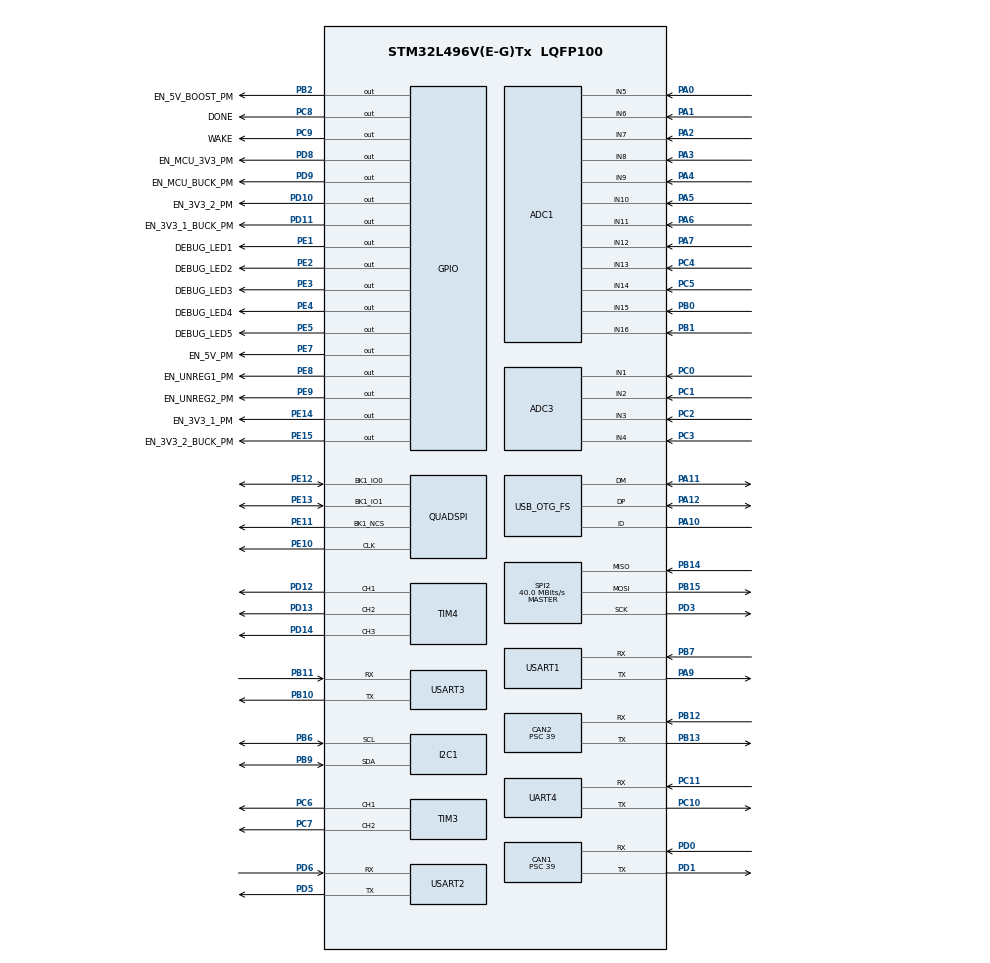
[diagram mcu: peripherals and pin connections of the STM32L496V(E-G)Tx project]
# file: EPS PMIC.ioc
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ADC1.Channel-0\#ChannelRegularConversion=ADC_CHANNEL_5
ADC1.Channel-1\#ChannelRegularConversion=ADC_CHANNEL_6
ADC1.Channel-10\#ChannelRegularConversion=ADC_CHANNEL_15
ADC1.Channel-11\#ChannelRegularConversion=ADC_CHANNEL_16
ADC1.Channel-12\#ChannelRegularConversion=ADC_CHANNEL_TEMPSENSOR
ADC1.Channel-13\#ChannelRegularConversion=ADC_CHANNEL_VBAT
ADC1.Channel-14\#ChannelRegularConversion=ADC_CHANNEL_VREFINT
ADC1.Channel-2\#ChannelRegularConversion=ADC_CHANNEL_7
ADC1.Channel-3\#ChannelRegularConversion=ADC_CHANNEL_8
ADC1.Channel-4\#ChannelRegularConversion=ADC_CHANNEL_9
ADC1.Channel-5\#ChannelRegularConversion=ADC_CHANNEL_10
ADC1.Channel-6\#ChannelRegularConversion=ADC_CHANNEL_11
ADC1.Channel-7\#ChannelRegularConversion=ADC_CHANNEL_12
ADC1.Channel-8\#ChannelRegularConversion=ADC_CHANNEL_13
ADC1.Channel-9\#ChannelRegularConversion=ADC_CHANNEL_14
ADC1.ContinuousConvMode=ENABLE
ADC1.DMAContinuousRequests=ENABLE
ADC1.EOCSelection=ADC_EOC_SEQ_CONV
ADC1.NbrOfConversion=15
ADC1.NbrOfConversionFlag=1
ADC1.OffsetNumber-0\#ChannelRegularConversion=ADC_OFFSET_NONE
ADC1.OffsetNumber-1\#ChannelRegularConversion=ADC_OFFSET_NONE
ADC1.OffsetNumber-10\#ChannelRegularConversion=ADC_OFFSET_NONE
ADC1.OffsetNumber-11\#ChannelRegularConversion=ADC_OFFSET_NONE
ADC1.OffsetNumber-12\#ChannelRegularConversion=ADC_OFFSET_NONE
ADC1.OffsetNumber-13\#ChannelRegularConversion=ADC_OFFSET_NONE
ADC1.OffsetNumber-14\#ChannelRegularConversion=ADC_OFFSET_NONE
ADC1.OffsetNumber-2\#ChannelRegularConversion=ADC_OFFSET_NONE
ADC1.OffsetNumber-3\#ChannelRegularConversion=ADC_OFFSET_NONE
ADC1.OffsetNumber-4\#ChannelRegularConversion=ADC_OFFSET_NONE
ADC1.OffsetNumber-5\#ChannelRegularConversion=ADC_OFFSET_NONE
ADC1.OffsetNumber-6\#ChannelRegularConversion=ADC_OFFSET_NONE
ADC1.OffsetNumber-7\#ChannelRegularConversion=ADC_OFFSET_NONE
ADC1.OffsetNumber-8\#ChannelRegularConversion=ADC_OFFSET_NONE
ADC1.OffsetNumber-9\#ChannelRegularConversion=ADC_OFFSET_NONE
ADC1.Rank-0\#ChannelRegularConversion=1
ADC1.Rank-1\#ChannelRegularConversion=2
ADC1.Rank-10\#ChannelRegularConversion=11
ADC1.Rank-11\#ChannelRegularConversion=12
ADC1.Rank-12\#ChannelRegularConversion=13
ADC1.Rank-13\#ChannelRegularConversion=14
ADC1.Rank-14\#ChannelRegularConversion=15
ADC1.Rank-2\#ChannelRegularConversion=3
ADC1.Rank-3\#ChannelRegularConversion=4
ADC1.Rank-4\#ChannelRegularConversion=5
ADC1.Rank-5\#ChannelRegularConversion=6
ADC1.Rank-6\#ChannelRegularConversion=7
ADC1.Rank-7\#ChannelRegularConversion=8
ADC1.Rank-8\#ChannelRegularConversion=9
ADC1.Rank-9\#ChannelRegularConversion=10
ADC1.SamplingTime-0\#ChannelRegularConversion=ADC_SAMPLETIME_247CYCLES_5
ADC1.SamplingTime-1\#ChannelRegularConversion=ADC_SAMPLETIME_247CYCLES_5
ADC1.SamplingTime-10\#ChannelRegularConversion=ADC_SAMPLETIME_247CYCLES_5
ADC1.SamplingTime-11\#ChannelRegularConversion=ADC_SAMPLETIME_247CYCLES_5
ADC1.SamplingTime-12\#ChannelRegularConversion=ADC_SAMPLETIME_247CYCLES_5
ADC1.SamplingTime-13\#ChannelRegularConversion=ADC_SAMPLETIME_247CYCLES_5
ADC1.SamplingTime-14\#ChannelRegularConversion=ADC_SAMPLETIME_247CYCLES_5
ADC1.SamplingTime-2\#ChannelRegularConversion=ADC_SAMPLETIME_247CYCLES_5
ADC1.SamplingTime-3\#ChannelRegularConversion=ADC_SAMPLETIME_247CYCLES_5
ADC1.SamplingTime-4\#ChannelRegularConversion=ADC_SAMPLETIME_247CYCLES_5
ADC1.SamplingTime-5\#ChannelRegularConversion=ADC_SAMPLETIME_247CYCLES_5
ADC1.SamplingTime-6\#ChannelRegularConversion=ADC_SAMPLETIME_247CYCLES_5
ADC1.SamplingTime-7\#ChannelRegularConversion=ADC_SAMPLETIME_247CYCLES_5
ADC1.SamplingTime-8\#ChannelRegularConversion=ADC_SAMPLETIME_247CYCLES_5
ADC1.SamplingTime-9\#ChannelRegularConversion=ADC_SAMPLETIME_247CYCLES_5
ADC1.master=1
ADC3.Channel-0\#ChannelRegularConversion=ADC_CHANNEL_1
ADC3.Channel-1\#ChannelRegularConversion=ADC_CHANNEL_2
ADC3.Channel-2\#ChannelRegularConversion=ADC_CHANNEL_3
ADC3.Channel-3\#ChannelRegularConversion=ADC_CHANNEL_4
ADC3.Channel-4\#ChannelRegularConversion=ADC_CHANNEL_TEMPSENSOR
ADC3.Channel-5\#ChannelRegularConversion=ADC_CHANNEL_VBAT
ADC3.ContinuousConvMode=ENABLE
ADC3.DMAContinuousRequests=ENABLE
ADC3.EOCSelection=ADC_EOC_SEQ_CONV
ADC3.NbrOfConversion=6
ADC3.NbrOfConversionFlag=1
ADC3.OffsetNumber-0\#ChannelRegularConversion=ADC_OFFSET_NONE
ADC3.OffsetNumber-1\#ChannelRegularConversion=ADC_OFFSET_NONE
ADC3.OffsetNumber-2\#ChannelRegularConversion=ADC_OFFSET_NONE
ADC3.OffsetNumber-3\#ChannelRegularConversion=ADC_OFFSET_NONE
ADC3.OffsetNumber-4\#ChannelRegularConversion=ADC_OFFSET_NONE
ADC3.OffsetNumber-5\#ChannelRegularConversion=ADC_OFFSET_NONE
ADC3.Rank-0\#ChannelRegularConversion=1
ADC3.Rank-1\#ChannelRegularConversion=2
ADC3.Rank-2\#ChannelRegularConversion=3
ADC3.Rank-3\#ChannelRegularConversion=4
ADC3.Rank-4\#ChannelRegularConversion=5
ADC3.Rank-5\#ChannelRegularConversion=6
ADC3.SamplingTime-0\#ChannelRegularConversion=ADC_SAMPLETIME_247CYCLES_5
ADC3.SamplingTime-1\#ChannelRegularConversion=ADC_SAMPLETIME_247CYCLES_5
ADC3.SamplingTime-2\#ChannelRegularConversion=ADC_SAMPLETIME_247CYCLES_5
ADC3.SamplingTime-3\#ChannelRegularConversion=ADC_SAMPLETIME_247CYCLES_5
ADC3.SamplingTime-4\#ChannelRegularConversion=ADC_SAMPLETIME_247CYCLES_5
ADC3.SamplingTime-5\#ChannelRegularConversion=ADC_SAMPLETIME_247CYCLES_5
CAN1.CalculateBaudRate=683760
CAN1.CalculateTimeBit=1462
CAN1.CalculateTimeQuantum=487.5
CAN1.Prescaler=39
CAN2.BS1=CAN_BS1_1TQ
CAN2.BS2=CAN_BS2_1TQ
CAN2.CalculateBaudRate=683760
CAN2.CalculateTimeBit=1462
CAN2.CalculateTimeQuantum=487.5
CAN2.Prescaler=39
Dma.ADC1.0.Direction=DMA_PERIPH_TO_MEMORY
Dma.ADC1.0.Instance=DMA1_Channel1
Dma.ADC1.0.MemDataAlignment=DMA_MDATAALIGN_HALFWORD
Dma.ADC1.0.MemInc=DMA_MINC_ENABLE
Dma.ADC1.0.Mode=DMA_CIRCULAR
Dma.ADC1.0.PeriphDataAlignment=DMA_PDATAALIGN_HALFWORD
Dma.ADC1.0.PeriphInc=DMA_PINC_DISABLE
Dma.ADC1.0.Priority=DMA_PRIORITY_HIGH
Dma.ADC3.1.Direction=DMA_PERIPH_TO_MEMORY
Dma.ADC3.1.Instance=DMA1_Channel3
Dma.ADC3.1.MemDataAlignment=DMA_MDATAALIGN_HALFWORD
Dma.ADC3.1.MemInc=DMA_MINC_ENABLE
Dma.ADC3.1.Mode=DMA_CIRCULAR
Dma.ADC3.1.PeriphDataAlignment=DMA_PDATAALIGN_HALFWORD
Dma.ADC3.1.PeriphInc=DMA_PINC_DISABLE
Dma.ADC3.1.Priority=DMA_PRIORITY_MEDIUM
Dma.Request0=ADC1
Dma.Request1=ADC3
I2C1.Timing=0x10D19CE4
Mcu.Family=STM32L4
Mcu.Name=STM32L496V(E-G)Tx
Mcu.Package=LQFP100
NVIC.DMA1_Channel1_IRQn=true\:0\:0\:false\:false\:true\:false\:true\:true
NVIC.DMA1_Channel3_IRQn=true\:0\:0\:false\:false\:true\:false\:true\:true
NVIC.PriorityGroup=NVIC_PRIORITYGROUP_4
NVIC.UART4_IRQn=true\:0\:0\:false\:false\:true\:true\:true\:true
NVIC.USART1_IRQn=true\:0\:0\:false\:false\:true\:true\:true\:true
NVIC.USART2_IRQn=true\:0\:0\:false\:false\:true\:true\:true\:true
NVIC.USART3_IRQn=true\:0\:0\:false\:false\:true\:true\:true\:true
PA0.Signal=ADCx_IN5
PA1.Signal=ADCx_IN6
PA10.Mode=OTG/Dual_Role_Device
PA10.Signal=USB_OTG_FS_ID
PA11.Mode=OTG/Dual_Role_Device
PA11.Signal=USB_OTG_FS_DM
PA12.Mode=OTG/Dual_Role_Device
PA12.Signal=USB_OTG_FS_DP
PA13\ (JTMS/SWDIO).Mode=JTAG_5_pins
PA13\ (JTMS/SWDIO).Signal=SYS_JTMS-SWDIO
PA14\ (JTCK/SWCLK).Mode=JTAG_5_pins
PA14\ (JTCK/SWCLK).Signal=SYS_JTCK-SWCLK
PA15\ (JTDI).Mode=JTAG_5_pins
PA15\ (JTDI).Signal=SYS_JTDI
PA2.Signal=ADCx_IN7
PA3.Signal=ADCx_IN8
PA4.Signal=ADCx_IN9
PA5.Signal=ADCx_IN10
PA6.Signal=ADCx_IN11
PA7.Signal=ADCx_IN12
PA9.Mode=Asynchronous
PA9.Signal=USART1_TX
PB0.Signal=ADCx_IN15
PB1.Signal=ADCx_IN16
PB10.Mode=Asynchronous
PB10.Signal=USART3_TX
PB11.Mode=Asynchronous
PB11.Signal=USART3_RX
PB12.Mode=CAN_Activate
PB12.Signal=CAN2_RX
PB13.Mode=CAN_Activate
PB13.Signal=CAN2_TX
PB14.Mode=Full_Duplex_Master
PB14.Signal=SPI2_MISO
PB15.Mode=Full_Duplex_Master
PB15.Signal=SPI2_MOSI
PB2.GPIO_Label=EN_5V_BOOST_PM
PB2.Signal=GPIO_Output
PB3\ (JTDO/TRACESWO).Mode=JTAG_5_pins
PB3\ (JTDO/TRACESWO).Signal=SYS_JTDO-SWO
PB4\ (NJTRST).Mode=JTAG_5_pins
PB4\ (NJTRST).Signal=SYS_JTRST
PB6.Mode=I2C
PB6.Signal=I2C1_SCL
PB7.Mode=Asynchronous
PB7.Signal=USART1_RX
PB9.Mode=I2C
PB9.Signal=I2C1_SDA
PC0.Signal=ADCx_IN1
PC1.Signal=ADCx_IN2
PC10.Mode=Asynchronous
PC10.Signal=UART4_TX
PC11.Mode=Asynchronous
PC11.Signal=UART4_RX
PC14-OSC32_IN\ (PC14).Mode=LSE-External-Oscillator
PC14-OSC32_IN\ (PC14).Signal=RCC_OSC32_IN
PC15-OSC32_OUT\ (PC15).Mode=LSE-External-Oscillator
PC15-OSC32_OUT\ (PC15).Signal=RCC_OSC32_OUT
PC2.Signal=ADCx_IN3
PC3.Signal=ADCx_IN4
PC4.Signal=ADCx_IN13
PC5.Signal=ADCx_IN14
PC6.Signal=S_TIM3_CH1
PC7.Signal=S_TIM3_CH2
PC8.GPIO_Label=DONE
PC8.Signal=GPIO_Output
PC9.GPIO_Label=WAKE
PC9.Signal=GPIO_Output
PD0.Mode=CAN_Activate
PD0.Signal=CAN1_RX
PD1.Mode=CAN_Activate
PD1.Signal=CAN1_TX
PD10.GPIO_Label=EN_3V3_2_PM
PD10.Signal=GPIO_Output
PD11.GPIO_Label=EN_3V3_1_BUCK_PM
PD11.Signal=GPIO_Output
PD12.Signal=S_TIM4_CH1
PD13.Signal=S_TIM4_CH2
PD14.Signal=S_TIM4_CH3
PD3.Mode=Full_Duplex_Master
PD3.Signal=SPI2_SCK
PD5.Mode=Asynchronous
PD5.Signal=USART2_TX
PD6.Mode=Asynchronous
PD6.Signal=USART2_RX
PD8.GPIO_Label=EN_MCU_3V3_PM
PD8.Signal=GPIO_Output
PD9.GPIO_Label=EN_MCU_BUCK_PM
PD9.Signal=GPIO_Output
PE1.GPIO_Label=DEBUG_LED1
PE1.Signal=GPIO_Output
PE10.Mode=Single Bank 1 2IOs
PE10.Signal=QUADSPI_CLK
PE11.Mode=Single Bank 1 2IOs
PE11.Signal=QUADSPI_BK1_NCS
PE12.Mode=Single Bank 1 2IOs
PE12.Signal=QUADSPI_BK1_IO0
PE13.Mode=Single Bank 1 2IOs
PE13.Signal=QUADSPI_BK1_IO1
PE14.GPIO_Label=EN_3V3_1_PM
PE14.Signal=GPIO_Output
PE15.GPIO_Label=EN_3V3_2_BUCK_PM
PE15.Signal=GPIO_Output
PE2.GPIO_Label=DEBUG_LED2
PE2.Signal=GPIO_Output
PE3.GPIO_Label=DEBUG_LED3
PE3.Signal=GPIO_Output
PE4.GPIO_Label=DEBUG_LED4
PE4.Signal=GPIO_Output
PE5.GPIO_Label=DEBUG_LED5
PE5.Signal=GPIO_Output
PE7.GPIO_Label=EN_5V_PM
PE7.Signal=GPIO_Output
PE8.GPIO_Label=EN_UNREG1_PM
PE8.Signal=GPIO_Output
PE9.GPIO_Label=EN_UNREG2_PM
PE9.Signal=GPIO_Output
PH0-OSC_IN\ (PH0).Mode=HSE-External-Oscillator
PH0-OSC_IN\ (PH0).Signal=RCC_OSC_IN
PH1-OSC_OUT\ (PH1).Mode=HSE-External-Oscillator
PH1-OSC_OUT\ (PH1).Signal=RCC_OSC_OUT
ProjectManager.HeapSize=0x200
ProjectManager.StackSize=0x400
ProjectManager.TargetToolchain=STM32CubeIDE
RCC.ADCFreq_Value=64000000
RCC.AHBFreq_Value=80000000
RCC.APB1Freq_Value=80000000
RCC.APB1TimFreq_Value=80000000
RCC.APB2Freq_Value=80000000
RCC.APB2TimFreq_Value=80000000
RCC.CK48CLockSelection=RCC_USBCLKSOURCE_HSI48
RCC.CortexFreq_Value=80000000
RCC.EnableCSSLSE=true
RCC.EnbaleCSS=true
RCC.HCLKFreq_Value=80000000
RCC.HSE_VALUE=16000000
RCC.HSI48_VALUE=48000000
RCC.HSI_VALUE=16000000
RCC.MSI_VALUE=4000000
RCC.PLLN=10
RCC.PLLSourceVirtual=RCC_PLLSOURCE_HSE
RCC.RTCClockSelection=RCC_RTCCLKSOURCE_LSE
RCC.SYSCLKFreq_VALUE=80000000
RCC.SYSCLKSource=RCC_SYSCLKSOURCE_PLLCLK
RCC.USBFreq_Value=48000000
RCC.VCOOutputFreq_Value=160000000
SH.ADCx_IN1.0=ADC3_IN1,IN1-Single-Ended
SH.ADCx_IN10.0=ADC1_IN10,IN10-Single-Ended
SH.ADCx_IN11.0=ADC1_IN11,IN11-Single-Ended
SH.ADCx_IN12.0=ADC1_IN12,IN12-Single-Ended
SH.ADCx_IN13.0=ADC1_IN13,IN13-Single-Ended
SH.ADCx_IN14.0=ADC1_IN14,IN14-Single-Ended
SH.ADCx_IN15.0=ADC1_IN15,IN15-Single-Ended
SH.ADCx_IN16.0=ADC1_IN16,IN16-Single-Ended
SH.ADCx_IN2.0=ADC3_IN2,IN2-Single-Ended
SH.ADCx_IN3.0=ADC3_IN3,IN3-Single-Ended
SH.ADCx_IN4.0=ADC3_IN4,IN4-Single-Ended
SH.ADCx_IN5.0=ADC1_IN5,IN5-Single-Ended
SH.ADCx_IN6.0=ADC1_IN6,IN6-Single-Ended
SH.ADCx_IN7.0=ADC1_IN7,IN7-Single-Ended
SH.ADCx_IN8.0=ADC1_IN8,IN8-Single-Ended
SH.ADCx_IN9.0=ADC1_IN9,IN9-Single-Ended
SH.S_TIM3_CH1.0=TIM3_CH1,PWM Generation1 CH1
SH.S_TIM3_CH2.0=TIM3_CH2,PWM Generation2 CH2
SH.S_TIM4_CH1.0=TIM4_CH1,PWM Generation1 CH1
SH.S_TIM4_CH2.0=TIM4_CH2,PWM Generation2 CH2
SH.S_TIM4_CH3.0=TIM4_CH3,PWM Generation3 CH3
SPI2.CalculateBaudRate=40.0 MBits/s
SPI2.Direction=SPI_DIRECTION_2LINES
SPI2.Mode=SPI_MODE_MASTER
SPI2.VirtualType=VM_MASTER
TIM3.Channel-PWM\ Generation1\ CH1=TIM_CHANNEL_1
TIM3.Channel-PWM\ Generation2\ CH2=TIM_CHANNEL_2
TIM4.Channel-PWM\ Generation1\ CH1=TIM_CHANNEL_1
TIM4.Channel-PWM\ Generation2\ CH2=TIM_CHANNEL_2
TIM4.Channel-PWM\ Generation3\ CH3=TIM_CHANNEL_3
USART1.VirtualMode-Asynchronous=VM_ASYNC
USART2.VirtualMode-Asynchronous=VM_ASYNC
USART3.VirtualMode-Asynchronous=VM_ASYNC
VP_ADC1_TempSens_Input.Mode=IN-TempSens
VP_ADC1_Vbat_Input.Mode=IN-Vbat
VP_ADC1_Vref_Input.Mode=IN-Vrefint
VP_ADC3_TempSens_Input.Mode=IN-TempSens
VP_ADC3_Vbat_Input.Mode=IN-Vbat
VP_RTC_VS_RTC_Activate.Mode=RTC_Enabled
board=custom

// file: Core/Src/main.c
/* USER CODE BEGIN Header */
/**
  ******************************************************************************
  * @file           : main.c
  * @brief          : Main program body
  ******************************************************************************
  * @attention
  *
  * Copyright (c) 2025 STMicroelectronics.
  * All rights reserved.
  *
  * This software is licensed under terms that can be found in the LICENSE file
  * in the root directory of this software component.
  * If no LICENSE file comes with this software, it is provided AS-IS.
  *
  ******************************************************************************
  */
/* USER CODE END Header */
#include "main.h"

/* USER CODE BEGIN Includes */
#include <stdio.h>
#include <string.h>
#include "pmic_functions.h"

/* USER CODE END Includes */

/* USER CODE BEGIN PTD */
int _write(int file, char* p, int len)
{
	for(int i=0;i<len;i++)
	{
		while(!LL_USART_IsActiveFlag_TXE(USART1));
		LL_USART_TransmitData8(USART1, *(p+i));
	}
	return len;
}

/* USER CODE END PTD */

CAN_HandleTypeDef hcan1;
CAN_HandleTypeDef hcan2;

I2C_HandleTypeDef hi2c1;

QSPI_HandleTypeDef hqspi;

/* USER CODE BEGIN PV */

extern uint8_t usart1_rx_flag;						// DEBUG
extern uint8_t usart1_rx_data;						// DEBUG

uint8_t  flagDMATC1 = 0;							// DMA TRANSFER COMPLETE CHANNEL 1 FLAG
uint8_t  flagDMATC3 = 0;							// DMA TRANSFER COMPLETE CHANNEL 3 FLAG
uint16_t adc1_Val[15];								// ADC1 VALUE
uint16_t adc3_Val[6];								// ADC3 VALUE

extern uint8_t sric_2_pmic_rx_buffer[20];			// SRIC-PMIC RX BUFFER
extern uint8_t sric_2_pmic_rx_complete_flag;		// SRIC-PMIC COMPLETE FLAG
extern uint8_t obc_2_pmic_rx_buffer[20];			// OBC-PMIC RX BUFFER
extern uint8_t obc_2_pmic_rx_complete_flag;			// OBC-PMIC COMPLETE FLAG

uint8_t pmic_2_sric_tx_buffer[20];					// PMIC-SR TX BUFFER
uint8_t pmic_2_obc_tx_buffer[20];					// PMIC-OBC TX BUFFER

/* USER CODE END PV */

void SystemClock_Config(void);
void PeriphCommonClock_Config(void);
static void MX_GPIO_Init(void);
static void MX_DMA_Init(void);
static void MX_CAN1_Init(void);
static void MX_CAN2_Init(void);
static void MX_QUADSPI_Init(void);
static void MX_RTC_Init(void);
static void MX_UART4_Init(void);
static void MX_USART1_UART_Init(void);
static void MX_USART2_UART_Init(void);
static void MX_USART3_UART_Init(void);
static void MX_ADC1_Init(void);
static void MX_ADC3_Init(void);
static void MX_USB_OTG_FS_USB_Init(void);
static void MX_I2C1_Init(void);
static void MX_SPI2_Init(void);
static void MX_TIM3_Init(void);
static void MX_TIM4_Init(void);

int main(void)
{

  /* MCU Configuration--------------------------------------------------------*/

  /* Reset of all peripherals, Initializes the Flash interface and the Systick. */
  HAL_Init();

  /* Configure the system clock */
  SystemClock_Config();

  /* Configure the peripherals common clocks */
  PeriphCommonClock_Config();

  /* Initialize all configured peripherals */
  MX_GPIO_Init();
  MX_DMA_Init();
  MX_CAN1_Init();
  MX_CAN2_Init();
  MX_QUADSPI_Init();
  MX_RTC_Init();
  MX_UART4_Init();
  MX_USART1_UART_Init();
  MX_USART2_UART_Init();
  MX_USART3_UART_Init();
  MX_ADC1_Init();
  MX_ADC3_Init();
  MX_USB_OTG_FS_USB_Init();
  MX_I2C1_Init();
  MX_SPI2_Init();
  MX_TIM3_Init();
  MX_TIM4_Init();
  /* USER CODE BEGIN 2 */

	LL_USART_EnableIT_RXNE(USART1);				// DEBUG
	LL_USART_EnableIT_RXNE(USART2);				// Uart  SR-PMIC
	LL_USART_EnableIT_RXNE(USART3);				// Uart  OBC-PMIC

	LL_DMA_ConfigAddresses(DMA1,				// DMA1_CHANNEL1 FOR ADC1
			LL_DMA_CHANNEL_1,
			LL_ADC_DMA_GetRegAddr(ADC1, LL_ADC_DMA_REG_REGULAR_DATA),
			(uint32_t)adc1_Val,
			LL_DMA_DIRECTION_PERIPH_TO_MEMORY);
	LL_DMA_SetDataLength(DMA1, LL_DMA_CHANNEL_1, 15);			// configure DMA length
	LL_DMA_EnableChannel(DMA1, LL_DMA_CHANNEL_1);				// enable DMA stream
	LL_ADC_Enable(ADC1);										// enable ADC
	LL_ADC_REG_StartConversion(ADC1);							// start conversion

	LL_DMA_ConfigAddresses(DMA1,								// DMA1_CHANNEL3 FOR ADC3
			LL_DMA_CHANNEL_3,
			LL_ADC_DMA_GetRegAddr(ADC3, LL_ADC_DMA_REG_REGULAR_DATA),
			(uint32_t)adc3_Val,
			LL_DMA_DIRECTION_PERIPH_TO_MEMORY);
	LL_DMA_SetDataLength(DMA1, LL_DMA_CHANNEL_3, 6);			// configure DMA length
	LL_DMA_EnableChannel(DMA1, LL_DMA_CHANNEL_3);				// enable DMA stream
	LL_ADC_Enable(ADC3);										// enable ADC
	LL_ADC_REG_StartConversion(ADC3);							// start conversion

	pmic_2_sric_tx_buffer[0]=0xEF;								// HEADER SETUP
	pmic_2_sric_tx_buffer[1]=0X00;
	pmic_2_obc_tx_buffer[0]=0xEB;
	pmic_2_obc_tx_buffer[1]=0X00;

  /* USER CODE END 2 */

  /* Infinite loop */
  /* USER CODE BEGIN WHILE */
  while (1)
  {

		while(!flagDMATC1);
		// clear flag
		flagDMATC1 = 0;
		while(!flagDMATC3);
		// clear flag
		flagDMATC3 = 0;

		/*--------------------------------------------------------------------------------------------*/
		/* UART SRIC_2_PMIC --------------------------------------------------------------------------*/
		/*--------------------------------------------------------------------------------------------*/
		if(sric_2_pmic_rx_complete_flag == 1)
		{
			sric_2_pmic_rx_complete_flag = 0;
			if(SRIC_2_PMIC_Check_CHKSUM(&sric_2_pmic_rx_buffer[0]) == 1){
				SRIC_2_PMIC_Parsing(&sric_2_pmic_rx_buffer[0], &sr2pm);
			}
		}
		/*--------------------------------------------------------------------------------------------*/
		/* UART OBC_2_PMIC ---------------------------------------------------------------------------*/
		/*--------------------------------------------------------------------------------------------*/
		if(obc_2_pmic_rx_complete_flag == 1)
		{
			obc_2_pmic_rx_complete_flag = 0;
			if(OBC_2_PMIC_Check_CHKSUM(&obc_2_pmic_rx_buffer[0]) == 1){
				OBC_2_PMIC_Parsing(&obc_2_pmic_rx_buffer[0], &obc2pm);
			}
		}
		/* CONFIGURE SATELLITE POWER -----------------------------------------------------------------*/
		PMIC_CONFIG_SAT_POWER( &obc2pm );

		/* SATELLITE PMIC TASKS HERE -----------------------------------------------------------------*/
		/* SATELLITE PMIC TASKS HERE -----------------------------------------------------------------*/
		/* SATELLITE PMIC TASKS HERE -----------------------------------------------------------------*/
		/* SATELLITE PMIC TASKS HERE -----------------------------------------------------------------*/
		/* SATELLITE PMIC TASKS HERE -----------------------------------------------------------------*/
		/* SATELLITE PMIC TASKS HERE -----------------------------------------------------------------*/
		/* SATELLITE PMIC TASKS HERE -----------------------------------------------------------------*/
		/* SATELLITE PMIC TASKS HERE -----------------------------------------------------------------*/
		/* SATELLITE PMIC TASKS HERE -----------------------------------------------------------------*/
		/* SATELLITE PMIC TASKS HERE -----------------------------------------------------------------*/

		/* SEND DATA PMIC_2_SRIC ---------------------------------------------------------------------*/
		SEND_DATA_UART(&pmic_2_sric_tx_buffer[0], USART2, 20);// CONTAINS CHKSUM GENRATOR
		/* SEND DATA PMIC_2_OBC ----------------------------------------------------------------------*/
		SEND_DATA_UART(&pmic_2_obc_tx_buffer[0], USART3, 20);

    /* USER CODE END WHILE */

  }
}

void SystemClock_Config(void)
{
  LL_FLASH_SetLatency(LL_FLASH_LATENCY_4);
  while(LL_FLASH_GetLatency()!= LL_FLASH_LATENCY_4)
  {
  }
  LL_PWR_SetRegulVoltageScaling(LL_PWR_REGU_VOLTAGE_SCALE1);
  while (LL_PWR_IsActiveFlag_VOS() != 0)
  {
  }
  LL_RCC_HSE_Enable();

   /* Wait till HSE is ready */
  while(LL_RCC_HSE_IsReady() != 1)
  {

  }
  LL_RCC_HSI48_Enable();

   /* Wait till HSI48 is ready */
  while(LL_RCC_HSI48_IsReady() != 1)
  {

  }
  LL_PWR_EnableBkUpAccess();
  LL_RCC_LSE_SetDriveCapability(LL_RCC_LSEDRIVE_LOW);
  LL_RCC_LSE_Enable();

   /* Wait till LSE is ready */
  while(LL_RCC_LSE_IsReady() != 1)
  {

  }
  LL_RCC_HSE_EnableCSS();
  LL_RCC_LSE_EnableCSS();
  LL_RCC_PLL_ConfigDomain_SYS(LL_RCC_PLLSOURCE_HSE, LL_RCC_PLLM_DIV_1, 10, LL_RCC_PLLR_DIV_2);
  LL_RCC_PLL_EnableDomain_SYS();
  LL_RCC_PLL_Enable();

   /* Wait till PLL is ready */
  while(LL_RCC_PLL_IsReady() != 1)
  {

  }
  LL_RCC_SetSysClkSource(LL_RCC_SYS_CLKSOURCE_PLL);

   /* Wait till System clock is ready */
  while(LL_RCC_GetSysClkSource() != LL_RCC_SYS_CLKSOURCE_STATUS_PLL)
  {

  }
  LL_RCC_SetAHBPrescaler(LL_RCC_SYSCLK_DIV_1);
  LL_RCC_SetAPB1Prescaler(LL_RCC_APB1_DIV_1);
  LL_RCC_SetAPB2Prescaler(LL_RCC_APB2_DIV_1);
  LL_SetSystemCoreClock(80000000);

   /* Update the time base */
  if (HAL_InitTick (TICK_INT_PRIORITY) != HAL_OK)
  {
    Error_Handler();
  }
}

void PeriphCommonClock_Config(void)
{
  LL_RCC_PLLSAI1_ConfigDomain_ADC(LL_RCC_PLLSOURCE_HSE, LL_RCC_PLLM_DIV_1, 8, LL_RCC_PLLSAI1R_DIV_2);
  LL_RCC_PLLSAI1_EnableDomain_ADC();
  LL_RCC_PLLSAI1_Enable();

   /* Wait till PLLSAI1 is ready */
  while(LL_RCC_PLLSAI1_IsReady() != 1)
  {

  }
  LL_RCC_SetUSBClockSource(LL_RCC_USB_CLKSOURCE_HSI48);
}

static void MX_ADC1_Init(void)
{

  LL_ADC_InitTypeDef ADC_InitStruct = {0};
  LL_ADC_REG_InitTypeDef ADC_REG_InitStruct = {0};
  LL_ADC_CommonInitTypeDef ADC_CommonInitStruct = {0};

  LL_GPIO_InitTypeDef GPIO_InitStruct = {0};

  LL_RCC_SetADCClockSource(LL_RCC_ADC_CLKSOURCE_PLLSAI1);

  /* Peripheral clock enable */
  LL_AHB2_GRP1_EnableClock(LL_AHB2_GRP1_PERIPH_ADC);

  LL_AHB2_GRP1_EnableClock(LL_AHB2_GRP1_PERIPH_GPIOA);
  LL_AHB2_GRP1_EnableClock(LL_AHB2_GRP1_PERIPH_GPIOC);
  LL_AHB2_GRP1_EnableClock(LL_AHB2_GRP1_PERIPH_GPIOB);
  /**ADC1 GPIO Configuration
  PA0   ------> ADC1_IN5
  PA1   ------> ADC1_IN6
  PA2   ------> ADC1_IN7
  PA3   ------> ADC1_IN8
  PA4   ------> ADC1_IN9
  PA5   ------> ADC1_IN10
  PA6   ------> ADC1_IN11
  PA7   ------> ADC1_IN12
  PC4   ------> ADC1_IN13
  PC5   ------> ADC1_IN14
  PB0   ------> ADC1_IN15
  PB1   ------> ADC1_IN16
  */
  GPIO_InitStruct.Pin = LL_GPIO_PIN_0|LL_GPIO_PIN_1|LL_GPIO_PIN_2|LL_GPIO_PIN_3
                          |LL_GPIO_PIN_4|LL_GPIO_PIN_5|LL_GPIO_PIN_6|LL_GPIO_PIN_7;
  GPIO_InitStruct.Mode = LL_GPIO_MODE_ANALOG;
  GPIO_InitStruct.Pull = LL_GPIO_PULL_NO;
  LL_GPIO_Init(GPIOA, &GPIO_InitStruct);

  GPIO_InitStruct.Pin = LL_GPIO_PIN_4|LL_GPIO_PIN_5;
  GPIO_InitStruct.Mode = LL_GPIO_MODE_ANALOG;
  GPIO_InitStruct.Pull = LL_GPIO_PULL_NO;
  LL_GPIO_Init(GPIOC, &GPIO_InitStruct);

  GPIO_InitStruct.Pin = LL_GPIO_PIN_0|LL_GPIO_PIN_1;
  GPIO_InitStruct.Mode = LL_GPIO_MODE_ANALOG;
  GPIO_InitStruct.Pull = LL_GPIO_PULL_NO;
  LL_GPIO_Init(GPIOB, &GPIO_InitStruct);

  /* ADC1 DMA Init */

  /* ADC1 Init */
  LL_DMA_SetPeriphRequest(DMA1, LL_DMA_CHANNEL_1, LL_DMA_REQUEST_0);

  LL_DMA_SetDataTransferDirection(DMA1, LL_DMA_CHANNEL_1, LL_DMA_DIRECTION_PERIPH_TO_MEMORY);

  LL_DMA_SetChannelPriorityLevel(DMA1, LL_DMA_CHANNEL_1, LL_DMA_PRIORITY_HIGH);

  LL_DMA_SetMode(DMA1, LL_DMA_CHANNEL_1, LL_DMA_MODE_CIRCULAR);

  LL_DMA_SetPeriphIncMode(DMA1, LL_DMA_CHANNEL_1, LL_DMA_PERIPH_NOINCREMENT);

  LL_DMA_SetMemoryIncMode(DMA1, LL_DMA_CHANNEL_1, LL_DMA_MEMORY_INCREMENT);

  LL_DMA_SetPeriphSize(DMA1, LL_DMA_CHANNEL_1, LL_DMA_PDATAALIGN_HALFWORD);

  LL_DMA_SetMemorySize(DMA1, LL_DMA_CHANNEL_1, LL_DMA_MDATAALIGN_HALFWORD);

  /** Common config
  */
  ADC_InitStruct.Resolution = LL_ADC_RESOLUTION_12B;
  ADC_InitStruct.DataAlignment = LL_ADC_DATA_ALIGN_RIGHT;
  ADC_InitStruct.LowPowerMode = LL_ADC_LP_MODE_NONE;
  LL_ADC_Init(ADC1, &ADC_InitStruct);
  ADC_REG_InitStruct.TriggerSource = LL_ADC_REG_TRIG_SOFTWARE;
  ADC_REG_InitStruct.SequencerLength = LL_ADC_REG_SEQ_SCAN_ENABLE_15RANKS;
  ADC_REG_InitStruct.SequencerDiscont = LL_ADC_REG_SEQ_DISCONT_DISABLE;
  ADC_REG_InitStruct.ContinuousMode = LL_ADC_REG_CONV_CONTINUOUS;
  ADC_REG_InitStruct.DMATransfer = LL_ADC_REG_DMA_TRANSFER_UNLIMITED;
  ADC_REG_InitStruct.Overrun = LL_ADC_REG_OVR_DATA_PRESERVED;
  LL_ADC_REG_Init(ADC1, &ADC_REG_InitStruct);
  LL_ADC_SetOverSamplingScope(ADC1, LL_ADC_OVS_DISABLE);
  LL_ADC_SetCommonPathInternalCh(__LL_ADC_COMMON_INSTANCE(ADC1), LL_ADC_PATH_INTERNAL_VREFINT|LL_ADC_PATH_INTERNAL_TEMPSENSOR|LL_ADC_PATH_INTERNAL_VBAT);
  ADC_CommonInitStruct.CommonClock = LL_ADC_CLOCK_ASYNC_DIV1;
  ADC_CommonInitStruct.Multimode = LL_ADC_MULTI_INDEPENDENT;
  LL_ADC_CommonInit(__LL_ADC_COMMON_INSTANCE(ADC1), &ADC_CommonInitStruct);

  /* Disable ADC deep power down (enabled by default after reset state) */
  LL_ADC_DisableDeepPowerDown(ADC1);
  /* Enable ADC internal voltage regulator */
  LL_ADC_EnableInternalRegulator(ADC1);
  /* Delay for ADC internal voltage regulator stabilization. */
  /* Compute number of CPU cycles to wait for, from delay in us. */
  /* Note: Variable divided by 2 to compensate partially */
  /* CPU processing cycles (depends on compilation optimization). */
  /* Note: If system core clock frequency is below 200kHz, wait time */
  /* is only a few CPU processing cycles. */
  uint32_t wait_loop_index;
  wait_loop_index = ((LL_ADC_DELAY_INTERNAL_REGUL_STAB_US * (SystemCoreClock / (100000 * 2))) / 10);
  while(wait_loop_index != 0)
  {
    wait_loop_index--;
  }

  /** Configure Regular Channel
  */
  LL_ADC_REG_SetSequencerRanks(ADC1, LL_ADC_REG_RANK_1, LL_ADC_CHANNEL_5);
  LL_ADC_SetChannelSamplingTime(ADC1, LL_ADC_CHANNEL_5, LL_ADC_SAMPLINGTIME_247CYCLES_5);
  LL_ADC_SetChannelSingleDiff(ADC1, LL_ADC_CHANNEL_5, LL_ADC_SINGLE_ENDED);

  /** Configure Regular Channel
  */
  LL_ADC_REG_SetSequencerRanks(ADC1, LL_ADC_REG_RANK_2, LL_ADC_CHANNEL_6);
  LL_ADC_SetChannelSamplingTime(ADC1, LL_ADC_CHANNEL_6, LL_ADC_SAMPLINGTIME_247CYCLES_5);
  LL_ADC_SetChannelSingleDiff(ADC1, LL_ADC_CHANNEL_6, LL_ADC_SINGLE_ENDED);

  /** Configure Regular Channel
  */
  LL_ADC_REG_SetSequencerRanks(ADC1, LL_ADC_REG_RANK_3, LL_ADC_CHANNEL_7);
  LL_ADC_SetChannelSamplingTime(ADC1, LL_ADC_CHANNEL_7, LL_ADC_SAMPLINGTIME_247CYCLES_5);
  LL_ADC_SetChannelSingleDiff(ADC1, LL_ADC_CHANNEL_7, LL_ADC_SINGLE_ENDED);

  /** Configure Regular Channel
  */
  LL_ADC_REG_SetSequencerRanks(ADC1, LL_ADC_REG_RANK_4, LL_ADC_CHANNEL_8);
  LL_ADC_SetChannelSamplingTime(ADC1, LL_ADC_CHANNEL_8, LL_ADC_SAMPLINGTIME_247CYCLES_5);
  LL_ADC_SetChannelSingleDiff(ADC1, LL_ADC_CHANNEL_8, LL_ADC_SINGLE_ENDED);

  /** Configure Regular Channel
  */
  LL_ADC_REG_SetSequencerRanks(ADC1, LL_ADC_REG_RANK_5, LL_ADC_CHANNEL_9);
  LL_ADC_SetChannelSamplingTime(ADC1, LL_ADC_CHANNEL_9, LL_ADC_SAMPLINGTIME_247CYCLES_5);
  LL_ADC_SetChannelSingleDiff(ADC1, LL_ADC_CHANNEL_9, LL_ADC_SINGLE_ENDED);

  /** Configure Regular Channel
  */
  LL_ADC_REG_SetSequencerRanks(ADC1, LL_ADC_REG_RANK_6, LL_ADC_CHANNEL_10);
  LL_ADC_SetChannelSamplingTime(ADC1, LL_ADC_CHANNEL_10, LL_ADC_SAMPLINGTIME_247CYCLES_5);
  LL_ADC_SetChannelSingleDiff(ADC1, LL_ADC_CHANNEL_10, LL_ADC_SINGLE_ENDED);

  /** Configure Regular Channel
  */
  LL_ADC_REG_SetSequencerRanks(ADC1, LL_ADC_REG_RANK_7, LL_ADC_CHANNEL_11);
  LL_ADC_SetChannelSamplingTime(ADC1, LL_ADC_CHANNEL_11, LL_ADC_SAMPLINGTIME_247CYCLES_5);
  LL_ADC_SetChannelSingleDiff(ADC1, LL_ADC_CHANNEL_11, LL_ADC_SINGLE_ENDED);

  /** Configure Regular Channel
  */
  LL_ADC_REG_SetSequencerRanks(ADC1, LL_ADC_REG_RANK_8, LL_ADC_CHANNEL_12);
  LL_ADC_SetChannelSamplingTime(ADC1, LL_ADC_CHANNEL_12, LL_ADC_SAMPLINGTIME_247CYCLES_5);
  LL_ADC_SetChannelSingleDiff(ADC1, LL_ADC_CHANNEL_12, LL_ADC_SINGLE_ENDED);

  /** Configure Regular Channel
  */
  LL_ADC_REG_SetSequencerRanks(ADC1, LL_ADC_REG_RANK_9, LL_ADC_CHANNEL_13);
  LL_ADC_SetChannelSamplingTime(ADC1, LL_ADC_CHANNEL_13, LL_ADC_SAMPLINGTIME_247CYCLES_5);
  LL_ADC_SetChannelSingleDiff(ADC1, LL_ADC_CHANNEL_13, LL_ADC_SINGLE_ENDED);

  /** Configure Regular Channel
  */
  LL_ADC_REG_SetSequencerRanks(ADC1, LL_ADC_REG_RANK_10, LL_ADC_CHANNEL_14);
  LL_ADC_SetChannelSamplingTime(ADC1, LL_ADC_CHANNEL_14, LL_ADC_SAMPLINGTIME_247CYCLES_5);
  LL_ADC_SetChannelSingleDiff(ADC1, LL_ADC_CHANNEL_14, LL_ADC_SINGLE_ENDED);

  /** Configure Regular Channel
  */
  LL_ADC_REG_SetSequencerRanks(ADC1, LL_ADC_REG_RANK_11, LL_ADC_CHANNEL_15);
  LL_ADC_SetChannelSamplingTime(ADC1, LL_ADC_CHANNEL_15, LL_ADC_SAMPLINGTIME_247CYCLES_5);
  LL_ADC_SetChannelSingleDiff(ADC1, LL_ADC_CHANNEL_15, LL_ADC_SINGLE_ENDED);

  /** Configure Regular Channel
  */
  LL_ADC_REG_SetSequencerRanks(ADC1, LL_ADC_REG_RANK_12, LL_ADC_CHANNEL_16);
  LL_ADC_SetChannelSamplingTime(ADC1, LL_ADC_CHANNEL_16, LL_ADC_SAMPLINGTIME_247CYCLES_5);
  LL_ADC_SetChannelSingleDiff(ADC1, LL_ADC_CHANNEL_16, LL_ADC_SINGLE_ENDED);

  /** Configure Regular Channel
  */
  LL_ADC_REG_SetSequencerRanks(ADC1, LL_ADC_REG_RANK_13, LL_ADC_CHANNEL_TEMPSENSOR);
  LL_ADC_SetChannelSamplingTime(ADC1, LL_ADC_CHANNEL_TEMPSENSOR, LL_ADC_SAMPLINGTIME_247CYCLES_5);
  LL_ADC_SetChannelSingleDiff(ADC1, LL_ADC_CHANNEL_TEMPSENSOR, LL_ADC_SINGLE_ENDED);

  /** Configure Regular Channel
  */
  LL_ADC_REG_SetSequencerRanks(ADC1, LL_ADC_REG_RANK_14, LL_ADC_CHANNEL_VBAT);
  LL_ADC_SetChannelSamplingTime(ADC1, LL_ADC_CHANNEL_VBAT, LL_ADC_SAMPLINGTIME_247CYCLES_5);
  LL_ADC_SetChannelSingleDiff(ADC1, LL_ADC_CHANNEL_VBAT, LL_ADC_SINGLE_ENDED);

  /** Configure Regular Channel
  */
  LL_ADC_REG_SetSequencerRanks(ADC1, LL_ADC_REG_RANK_15, LL_ADC_CHANNEL_VREFINT);
  LL_ADC_SetChannelSamplingTime(ADC1, LL_ADC_CHANNEL_VREFINT, LL_ADC_SAMPLINGTIME_247CYCLES_5);
  LL_ADC_SetChannelSingleDiff(ADC1, LL_ADC_CHANNEL_VREFINT, LL_ADC_SINGLE_ENDED);

}

static void MX_ADC3_Init(void)
{

  LL_ADC_InitTypeDef ADC_InitStruct = {0};
  LL_ADC_REG_InitTypeDef ADC_REG_InitStruct = {0};
  LL_ADC_CommonInitTypeDef ADC_CommonInitStruct = {0};

  LL_GPIO_InitTypeDef GPIO_InitStruct = {0};

  LL_RCC_SetADCClockSource(LL_RCC_ADC_CLKSOURCE_PLLSAI1);

  /* Peripheral clock enable */
  LL_AHB2_GRP1_EnableClock(LL_AHB2_GRP1_PERIPH_ADC);

  LL_AHB2_GRP1_EnableClock(LL_AHB2_GRP1_PERIPH_GPIOC);
  /**ADC3 GPIO Configuration
  PC0   ------> ADC3_IN1
  PC1   ------> ADC3_IN2
  PC2   ------> ADC3_IN3
  PC3   ------> ADC3_IN4
  */
  GPIO_InitStruct.Pin = LL_GPIO_PIN_0|LL_GPIO_PIN_1|LL_GPIO_PIN_2|LL_GPIO_PIN_3;
  GPIO_InitStruct.Mode = LL_GPIO_MODE_ANALOG;
  GPIO_InitStruct.Pull = LL_GPIO_PULL_NO;
  LL_GPIO_Init(GPIOC, &GPIO_InitStruct);

  /* ADC3 DMA Init */

  /* ADC3 Init */
  LL_DMA_SetPeriphRequest(DMA1, LL_DMA_CHANNEL_3, LL_DMA_REQUEST_0);

  LL_DMA_SetDataTransferDirection(DMA1, LL_DMA_CHANNEL_3, LL_DMA_DIRECTION_PERIPH_TO_MEMORY);

  LL_DMA_SetChannelPriorityLevel(DMA1, LL_DMA_CHANNEL_3, LL_DMA_PRIORITY_MEDIUM);

  LL_DMA_SetMode(DMA1, LL_DMA_CHANNEL_3, LL_DMA_MODE_CIRCULAR);

  LL_DMA_SetPeriphIncMode(DMA1, LL_DMA_CHANNEL_3, LL_DMA_PERIPH_NOINCREMENT);

  LL_DMA_SetMemoryIncMode(DMA1, LL_DMA_CHANNEL_3, LL_DMA_MEMORY_INCREMENT);

  LL_DMA_SetPeriphSize(DMA1, LL_DMA_CHANNEL_3, LL_DMA_PDATAALIGN_HALFWORD);

  LL_DMA_SetMemorySize(DMA1, LL_DMA_CHANNEL_3, LL_DMA_MDATAALIGN_HALFWORD);

  /** Common config
  */
  ADC_InitStruct.Resolution = LL_ADC_RESOLUTION_12B;
  ADC_InitStruct.DataAlignment = LL_ADC_DATA_ALIGN_RIGHT;
  ADC_InitStruct.LowPowerMode = LL_ADC_LP_MODE_NONE;
  LL_ADC_Init(ADC3, &ADC_InitStruct);
  ADC_REG_InitStruct.TriggerSource = LL_ADC_REG_TRIG_SOFTWARE;
  ADC_REG_InitStruct.SequencerLength = LL_ADC_REG_SEQ_SCAN_ENABLE_6RANKS;
  ADC_REG_InitStruct.SequencerDiscont = LL_ADC_REG_SEQ_DISCONT_DISABLE;
  ADC_REG_InitStruct.ContinuousMode = LL_ADC_REG_CONV_CONTINUOUS;
  ADC_REG_InitStruct.DMATransfer = LL_ADC_REG_DMA_TRANSFER_UNLIMITED;
  ADC_REG_InitStruct.Overrun = LL_ADC_REG_OVR_DATA_PRESERVED;
  LL_ADC_REG_Init(ADC3, &ADC_REG_InitStruct);
  LL_ADC_SetOverSamplingScope(ADC3, LL_ADC_OVS_DISABLE);
  LL_ADC_SetCommonPathInternalCh(__LL_ADC_COMMON_INSTANCE(ADC3), LL_ADC_PATH_INTERNAL_TEMPSENSOR|LL_ADC_PATH_INTERNAL_VBAT);
  ADC_CommonInitStruct.CommonClock = LL_ADC_CLOCK_ASYNC_DIV1;
  LL_ADC_CommonInit(__LL_ADC_COMMON_INSTANCE(ADC3), &ADC_CommonInitStruct);

  /* Disable ADC deep power down (enabled by default after reset state) */
  LL_ADC_DisableDeepPowerDown(ADC3);
  /* Enable ADC internal voltage regulator */
  LL_ADC_EnableInternalRegulator(ADC3);
  /* Delay for ADC internal voltage regulator stabilization. */
  /* Compute number of CPU cycles to wait for, from delay in us. */
  /* Note: Variable divided by 2 to compensate partially */
  /* CPU processing cycles (depends on compilation optimization). */
  /* Note: If system core clock frequency is below 200kHz, wait time */
  /* is only a few CPU processing cycles. */
  uint32_t wait_loop_index;
  wait_loop_index = ((LL_ADC_DELAY_INTERNAL_REGUL_STAB_US * (SystemCoreClock / (100000 * 2))) / 10);
  while(wait_loop_index != 0)
  {
    wait_loop_index--;
  }

  /** Configure Regular Channel
  */
  LL_ADC_REG_SetSequencerRanks(ADC3, LL_ADC_REG_RANK_1, LL_ADC_CHANNEL_1);
  LL_ADC_SetChannelSamplingTime(ADC3, LL_ADC_CHANNEL_1, LL_ADC_SAMPLINGTIME_247CYCLES_5);
  LL_ADC_SetChannelSingleDiff(ADC3, LL_ADC_CHANNEL_1, LL_ADC_SINGLE_ENDED);

  /** Configure Regular Channel
  */
  LL_ADC_REG_SetSequencerRanks(ADC3, LL_ADC_REG_RANK_2, LL_ADC_CHANNEL_2);
  LL_ADC_SetChannelSamplingTime(ADC3, LL_ADC_CHANNEL_2, LL_ADC_SAMPLINGTIME_247CYCLES_5);
  LL_ADC_SetChannelSingleDiff(ADC3, LL_ADC_CHANNEL_2, LL_ADC_SINGLE_ENDED);

  /** Configure Regular Channel
  */
  LL_ADC_REG_SetSequencerRanks(ADC3, LL_ADC_REG_RANK_3, LL_ADC_CHANNEL_3);
  LL_ADC_SetChannelSamplingTime(ADC3, LL_ADC_CHANNEL_3, LL_ADC_SAMPLINGTIME_247CYCLES_5);
  LL_ADC_SetChannelSingleDiff(ADC3, LL_ADC_CHANNEL_3, LL_ADC_SINGLE_ENDED);

  /** Configure Regular Channel
  */
  LL_ADC_REG_SetSequencerRanks(ADC3, LL_ADC_REG_RANK_4, LL_ADC_CHANNEL_4);
  LL_ADC_SetChannelSamplingTime(ADC3, LL_ADC_CHANNEL_4, LL_ADC_SAMPLINGTIME_247CYCLES_5);
  LL_ADC_SetChannelSingleDiff(ADC3, LL_ADC_CHANNEL_4, LL_ADC_SINGLE_ENDED);

  /** Configure Regular Channel
  */
  LL_ADC_REG_SetSequencerRanks(ADC3, LL_ADC_REG_RANK_5, LL_ADC_CHANNEL_TEMPSENSOR);
  LL_ADC_SetChannelSamplingTime(ADC3, LL_ADC_CHANNEL_TEMPSENSOR, LL_ADC_SAMPLINGTIME_247CYCLES_5);
  LL_ADC_SetChannelSingleDiff(ADC3, LL_ADC_CHANNEL_TEMPSENSOR, LL_ADC_SINGLE_ENDED);

  /** Configure Regular Channel
  */
  LL_ADC_REG_SetSequencerRanks(ADC3, LL_ADC_REG_RANK_6, LL_ADC_CHANNEL_VBAT);
  LL_ADC_SetChannelSamplingTime(ADC3, LL_ADC_CHANNEL_VBAT, LL_ADC_SAMPLINGTIME_247CYCLES_5);
  LL_ADC_SetChannelSingleDiff(ADC3, LL_ADC_CHANNEL_VBAT, LL_ADC_SINGLE_ENDED);

}

static void MX_CAN1_Init(void)
{

  hcan1.Instance = CAN1;
  hcan1.Init.Prescaler = 39;
  hcan1.Init.Mode = CAN_MODE_NORMAL;
  hcan1.Init.SyncJumpWidth = CAN_SJW_1TQ;
  hcan1.Init.TimeSeg1 = CAN_BS1_1TQ;
  hcan1.Init.TimeSeg2 = CAN_BS2_1TQ;
  hcan1.Init.TimeTriggeredMode = DISABLE;
  hcan1.Init.AutoBusOff = DISABLE;
  hcan1.Init.AutoWakeUp = DISABLE;
  hcan1.Init.AutoRetransmission = DISABLE;
  hcan1.Init.ReceiveFifoLocked = DISABLE;
  hcan1.Init.TransmitFifoPriority = DISABLE;
  if (HAL_CAN_Init(&hcan1) != HAL_OK)
  {
    Error_Handler();
  }

}

static void MX_CAN2_Init(void)
{

  hcan2.Instance = CAN2;
  hcan2.Init.Prescaler = 39;
  hcan2.Init.Mode = CAN_MODE_NORMAL;
  hcan2.Init.SyncJumpWidth = CAN_SJW_1TQ;
  hcan2.Init.TimeSeg1 = CAN_BS1_1TQ;
  hcan2.Init.TimeSeg2 = CAN_BS2_1TQ;
  hcan2.Init.TimeTriggeredMode = DISABLE;
  hcan2.Init.AutoBusOff = DISABLE;
  hcan2.Init.AutoWakeUp = DISABLE;
  hcan2.Init.AutoRetransmission = DISABLE;
  hcan2.Init.ReceiveFifoLocked = DISABLE;
  hcan2.Init.TransmitFifoPriority = DISABLE;
  if (HAL_CAN_Init(&hcan2) != HAL_OK)
  {
    Error_Handler();
  }

}

static void MX_I2C1_Init(void)
{

  hi2c1.Instance = I2C1;
  hi2c1.Init.Timing = 0x10D19CE4;
  hi2c1.Init.OwnAddress1 = 0;
  hi2c1.Init.AddressingMode = I2C_ADDRESSINGMODE_7BIT;
  hi2c1.Init.DualAddressMode = I2C_DUALADDRESS_DISABLE;
  hi2c1.Init.OwnAddress2 = 0;
  hi2c1.Init.OwnAddress2Masks = I2C_OA2_NOMASK;
  hi2c1.Init.GeneralCallMode = I2C_GENERALCALL_DISABLE;
  hi2c1.Init.NoStretchMode = I2C_NOSTRETCH_DISABLE;
  if (HAL_I2C_Init(&hi2c1) != HAL_OK)
  {
    Error_Handler();
  }

  /** Configure Analogue filter
  */
  if (HAL_I2CEx_ConfigAnalogFilter(&hi2c1, I2C_ANALOGFILTER_ENABLE) != HAL_OK)
  {
    Error_Handler();
  }

  /** Configure Digital filter
  */
  if (HAL_I2CEx_ConfigDigitalFilter(&hi2c1, 0) != HAL_OK)
  {
    Error_Handler();
  }

}

static void MX_QUADSPI_Init(void)
{

  /* QUADSPI parameter configuration*/
  hqspi.Instance = QUADSPI;
  hqspi.Init.ClockPrescaler = 255;
  hqspi.Init.FifoThreshold = 1;
  hqspi.Init.SampleShifting = QSPI_SAMPLE_SHIFTING_NONE;
  hqspi.Init.FlashSize = 1;
  hqspi.Init.ChipSelectHighTime = QSPI_CS_HIGH_TIME_1_CYCLE;
  hqspi.Init.ClockMode = QSPI_CLOCK_MODE_0;
  hqspi.Init.FlashID = QSPI_FLASH_ID_1;
  hqspi.Init.DualFlash = QSPI_DUALFLASH_DISABLE;
  if (HAL_QSPI_Init(&hqspi) != HAL_OK)
  {
    Error_Handler();
  }

}

static void MX_RTC_Init(void)
{

  LL_RTC_InitTypeDef RTC_InitStruct = {0};

  if(LL_RCC_GetRTCClockSource() != LL_RCC_RTC_CLKSOURCE_LSE)
  {
    FlagStatus pwrclkchanged = RESET;
    /* Update LSE configuration in Backup Domain control register */
    /* Requires to enable write access to Backup Domain if necessary */
    if (LL_APB1_GRP1_IsEnabledClock (LL_APB1_GRP1_PERIPH_PWR) != 1U)
    {
      /* Enables the PWR Clock and Enables access to the backup domain */
      LL_APB1_GRP1_EnableClock(LL_APB1_GRP1_PERIPH_PWR);
      pwrclkchanged = SET;
    }
    if (LL_PWR_IsEnabledBkUpAccess () != 1U)
    {
      /* Enable write access to Backup domain */
      LL_PWR_EnableBkUpAccess();
      while (LL_PWR_IsEnabledBkUpAccess () == 0U)
      {
      }
    }
    LL_RCC_ForceBackupDomainReset();
    LL_RCC_ReleaseBackupDomainReset();
  LL_RCC_LSE_SetDriveCapability(LL_RCC_LSEDRIVE_LOW);
    LL_RCC_LSE_Enable();

   /* Wait till LSE is ready */
    while(LL_RCC_LSE_IsReady() != 1)
    {
    }
    LL_RCC_SetRTCClockSource(LL_RCC_RTC_CLKSOURCE_LSE);
    /* Restore clock configuration if changed */
    if (pwrclkchanged == SET)
    {
      LL_APB1_GRP1_DisableClock(LL_APB1_GRP1_PERIPH_PWR);
    }
  }

  /* Peripheral clock enable */
  LL_RCC_EnableRTC();

  /** Initialize RTC and set the Time and Date
  */
  RTC_InitStruct.HourFormat = LL_RTC_HOURFORMAT_24HOUR;
  RTC_InitStruct.AsynchPrescaler = 127;
  RTC_InitStruct.SynchPrescaler = 255;
  LL_RTC_Init(RTC, &RTC_InitStruct);

}

static void MX_SPI2_Init(void)
{

  LL_SPI_InitTypeDef SPI_InitStruct = {0};

  LL_GPIO_InitTypeDef GPIO_InitStruct = {0};

  /* Peripheral clock enable */
  LL_APB1_GRP1_EnableClock(LL_APB1_GRP1_PERIPH_SPI2);

  LL_AHB2_GRP1_EnableClock(LL_AHB2_GRP1_PERIPH_GPIOB);
  LL_AHB2_GRP1_EnableClock(LL_AHB2_GRP1_PERIPH_GPIOD);
  /**SPI2 GPIO Configuration
  PB14   ------> SPI2_MISO
  PB15   ------> SPI2_MOSI
  PD3   ------> SPI2_SCK
  */
  GPIO_InitStruct.Pin = LL_GPIO_PIN_14|LL_GPIO_PIN_15;
  GPIO_InitStruct.Mode = LL_GPIO_MODE_ALTERNATE;
  GPIO_InitStruct.Speed = LL_GPIO_SPEED_FREQ_VERY_HIGH;
  GPIO_InitStruct.OutputType = LL_GPIO_OUTPUT_PUSHPULL;
  GPIO_InitStruct.Pull = LL_GPIO_PULL_NO;
  GPIO_InitStruct.Alternate = LL_GPIO_AF_5;
  LL_GPIO_Init(GPIOB, &GPIO_InitStruct);

  GPIO_InitStruct.Pin = LL_GPIO_PIN_3;
  GPIO_InitStruct.Mode = LL_GPIO_MODE_ALTERNATE;
  GPIO_InitStruct.Speed = LL_GPIO_SPEED_FREQ_VERY_HIGH;
  GPIO_InitStruct.OutputType = LL_GPIO_OUTPUT_PUSHPULL;
  GPIO_InitStruct.Pull = LL_GPIO_PULL_NO;
  GPIO_InitStruct.Alternate = GPIO_AF3_SPI2;
  LL_GPIO_Init(GPIOD, &GPIO_InitStruct);

  /* SPI2 parameter configuration*/
  SPI_InitStruct.TransferDirection = LL_SPI_FULL_DUPLEX;
  SPI_InitStruct.Mode = LL_SPI_MODE_MASTER;
  SPI_InitStruct.DataWidth = LL_SPI_DATAWIDTH_4BIT;
  SPI_InitStruct.ClockPolarity = LL_SPI_POLARITY_LOW;
  SPI_InitStruct.ClockPhase = LL_SPI_PHASE_1EDGE;
  SPI_InitStruct.NSS = LL_SPI_NSS_SOFT;
  SPI_InitStruct.BaudRate = LL_SPI_BAUDRATEPRESCALER_DIV2;
  SPI_InitStruct.BitOrder = LL_SPI_MSB_FIRST;
  SPI_InitStruct.CRCCalculation = LL_SPI_CRCCALCULATION_DISABLE;
  SPI_InitStruct.CRCPoly = 7;
  LL_SPI_Init(SPI2, &SPI_InitStruct);
  LL_SPI_SetStandard(SPI2, LL_SPI_PROTOCOL_MOTOROLA);
  LL_SPI_EnableNSSPulseMgt(SPI2);

}

static void MX_TIM3_Init(void)
{

  LL_TIM_InitTypeDef TIM_InitStruct = {0};
  LL_TIM_OC_InitTypeDef TIM_OC_InitStruct = {0};

  LL_GPIO_InitTypeDef GPIO_InitStruct = {0};

  /* Peripheral clock enable */
  LL_APB1_GRP1_EnableClock(LL_APB1_GRP1_PERIPH_TIM3);

  TIM_InitStruct.Prescaler = 0;
  TIM_InitStruct.CounterMode = LL_TIM_COUNTERMODE_UP;
  TIM_InitStruct.Autoreload = 65535;
  TIM_InitStruct.ClockDivision = LL_TIM_CLOCKDIVISION_DIV1;
  LL_TIM_Init(TIM3, &TIM_InitStruct);
  LL_TIM_DisableARRPreload(TIM3);
  LL_TIM_OC_EnablePreload(TIM3, LL_TIM_CHANNEL_CH1);
  TIM_OC_InitStruct.OCMode = LL_TIM_OCMODE_PWM1;
  TIM_OC_InitStruct.OCState = LL_TIM_OCSTATE_DISABLE;
  TIM_OC_InitStruct.OCNState = LL_TIM_OCSTATE_DISABLE;
  TIM_OC_InitStruct.CompareValue = 0;
  TIM_OC_InitStruct.OCPolarity = LL_TIM_OCPOLARITY_HIGH;
  LL_TIM_OC_Init(TIM3, LL_TIM_CHANNEL_CH1, &TIM_OC_InitStruct);
  LL_TIM_OC_DisableFast(TIM3, LL_TIM_CHANNEL_CH1);
  LL_TIM_OC_EnablePreload(TIM3, LL_TIM_CHANNEL_CH2);
  LL_TIM_OC_Init(TIM3, LL_TIM_CHANNEL_CH2, &TIM_OC_InitStruct);
  LL_TIM_OC_DisableFast(TIM3, LL_TIM_CHANNEL_CH2);
  LL_TIM_SetOCRefClearInputSource(TIM3, LL_TIM_OCREF_CLR_INT_NC);
  LL_TIM_DisableExternalClock(TIM3);
  LL_TIM_ConfigETR(TIM3, LL_TIM_ETR_POLARITY_NONINVERTED, LL_TIM_ETR_PRESCALER_DIV1, LL_TIM_ETR_FILTER_FDIV1);
  LL_TIM_SetTriggerOutput(TIM3, LL_TIM_TRGO_RESET);
  LL_TIM_DisableMasterSlaveMode(TIM3);
  LL_AHB2_GRP1_EnableClock(LL_AHB2_GRP1_PERIPH_GPIOC);
  /**TIM3 GPIO Configuration
  PC6   ------> TIM3_CH1
  PC7   ------> TIM3_CH2
  */
  GPIO_InitStruct.Pin = LL_GPIO_PIN_6|LL_GPIO_PIN_7;
  GPIO_InitStruct.Mode = LL_GPIO_MODE_ALTERNATE;
  GPIO_InitStruct.Speed = LL_GPIO_SPEED_FREQ_LOW;
  GPIO_InitStruct.OutputType = LL_GPIO_OUTPUT_PUSHPULL;
  GPIO_InitStruct.Pull = LL_GPIO_PULL_NO;
  GPIO_InitStruct.Alternate = LL_GPIO_AF_2;
  LL_GPIO_Init(GPIOC, &GPIO_InitStruct);

}

static void MX_TIM4_Init(void)
{

  LL_TIM_InitTypeDef TIM_InitStruct = {0};
  LL_TIM_OC_InitTypeDef TIM_OC_InitStruct = {0};

  LL_GPIO_InitTypeDef GPIO_InitStruct = {0};

  /* Peripheral clock enable */
  LL_APB1_GRP1_EnableClock(LL_APB1_GRP1_PERIPH_TIM4);

  TIM_InitStruct.Prescaler = 0;
  TIM_InitStruct.CounterMode = LL_TIM_COUNTERMODE_UP;
  TIM_InitStruct.Autoreload = 65535;
  TIM_InitStruct.ClockDivision = LL_TIM_CLOCKDIVISION_DIV1;
  LL_TIM_Init(TIM4, &TIM_InitStruct);
  LL_TIM_DisableARRPreload(TIM4);
  LL_TIM_OC_EnablePreload(TIM4, LL_TIM_CHANNEL_CH1);
  TIM_OC_InitStruct.OCMode = LL_TIM_OCMODE_PWM1;
  TIM_OC_InitStruct.OCState = LL_TIM_OCSTATE_DISABLE;
  TIM_OC_InitStruct.OCNState = LL_TIM_OCSTATE_DISABLE;
  TIM_OC_InitStruct.CompareValue = 0;
  TIM_OC_InitStruct.OCPolarity = LL_TIM_OCPOLARITY_HIGH;
  LL_TIM_OC_Init(TIM4, LL_TIM_CHANNEL_CH1, &TIM_OC_InitStruct);
  LL_TIM_OC_DisableFast(TIM4, LL_TIM_CHANNEL_CH1);
  LL_TIM_OC_EnablePreload(TIM4, LL_TIM_CHANNEL_CH2);
  LL_TIM_OC_Init(TIM4, LL_TIM_CHANNEL_CH2, &TIM_OC_InitStruct);
  LL_TIM_OC_DisableFast(TIM4, LL_TIM_CHANNEL_CH2);
  LL_TIM_OC_EnablePreload(TIM4, LL_TIM_CHANNEL_CH3);
  LL_TIM_OC_Init(TIM4, LL_TIM_CHANNEL_CH3, &TIM_OC_InitStruct);
  LL_TIM_OC_DisableFast(TIM4, LL_TIM_CHANNEL_CH3);
  LL_TIM_SetOCRefClearInputSource(TIM4, LL_TIM_OCREF_CLR_INT_NC);
  LL_TIM_DisableExternalClock(TIM4);
  LL_TIM_ConfigETR(TIM4, LL_TIM_ETR_POLARITY_NONINVERTED, LL_TIM_ETR_PRESCALER_DIV1, LL_TIM_ETR_FILTER_FDIV1);
  LL_TIM_SetTriggerOutput(TIM4, LL_TIM_TRGO_RESET);
  LL_TIM_DisableMasterSlaveMode(TIM4);
  LL_AHB2_GRP1_EnableClock(LL_AHB2_GRP1_PERIPH_GPIOD);
  /**TIM4 GPIO Configuration
  PD12   ------> TIM4_CH1
  PD13   ------> TIM4_CH2
  PD14   ------> TIM4_CH3
  */
  GPIO_InitStruct.Pin = LL_GPIO_PIN_12|LL_GPIO_PIN_13|LL_GPIO_PIN_14;
  GPIO_InitStruct.Mode = LL_GPIO_MODE_ALTERNATE;
  GPIO_InitStruct.Speed = LL_GPIO_SPEED_FREQ_LOW;
  GPIO_InitStruct.OutputType = LL_GPIO_OUTPUT_PUSHPULL;
  GPIO_InitStruct.Pull = LL_GPIO_PULL_NO;
  GPIO_InitStruct.Alternate = LL_GPIO_AF_2;
  LL_GPIO_Init(GPIOD, &GPIO_InitStruct);

}

static void MX_UART4_Init(void)
{

  LL_USART_InitTypeDef UART_InitStruct = {0};

  LL_GPIO_InitTypeDef GPIO_InitStruct = {0};

  LL_RCC_SetUARTClockSource(LL_RCC_UART4_CLKSOURCE_PCLK1);

  /* Peripheral clock enable */
  LL_APB1_GRP1_EnableClock(LL_APB1_GRP1_PERIPH_UART4);

  LL_AHB2_GRP1_EnableClock(LL_AHB2_GRP1_PERIPH_GPIOC);
  /**UART4 GPIO Configuration
  PC10   ------> UART4_TX
  PC11   ------> UART4_RX
  */
  GPIO_InitStruct.Pin = LL_GPIO_PIN_10|LL_GPIO_PIN_11;
  GPIO_InitStruct.Mode = LL_GPIO_MODE_ALTERNATE;
  GPIO_InitStruct.Speed = LL_GPIO_SPEED_FREQ_VERY_HIGH;
  GPIO_InitStruct.OutputType = LL_GPIO_OUTPUT_PUSHPULL;
  GPIO_InitStruct.Pull = LL_GPIO_PULL_NO;
  GPIO_InitStruct.Alternate = LL_GPIO_AF_8;
  LL_GPIO_Init(GPIOC, &GPIO_InitStruct);

  /* UART4 interrupt Init */
  NVIC_SetPriority(UART4_IRQn, NVIC_EncodePriority(NVIC_GetPriorityGrouping(),0, 0));
  NVIC_EnableIRQ(UART4_IRQn);

  UART_InitStruct.BaudRate = 115200;
  UART_InitStruct.DataWidth = LL_USART_DATAWIDTH_8B;
  UART_InitStruct.StopBits = LL_USART_STOPBITS_1;
  UART_InitStruct.Parity = LL_USART_PARITY_NONE;
  UART_InitStruct.TransferDirection = LL_USART_DIRECTION_TX_RX;
  UART_InitStruct.HardwareFlowControl = LL_USART_HWCONTROL_NONE;
  UART_InitStruct.OverSampling = LL_USART_OVERSAMPLING_16;
  LL_USART_Init(UART4, &UART_InitStruct);
  LL_USART_ConfigAsyncMode(UART4);
  LL_USART_Enable(UART4);

}

static void MX_USART1_UART_Init(void)
{

  LL_USART_InitTypeDef USART_InitStruct = {0};

  LL_GPIO_InitTypeDef GPIO_InitStruct = {0};

  LL_RCC_SetUSARTClockSource(LL_RCC_USART1_CLKSOURCE_PCLK2);

  /* Peripheral clock enable */
  LL_APB2_GRP1_EnableClock(LL_APB2_GRP1_PERIPH_USART1);

  LL_AHB2_GRP1_EnableClock(LL_AHB2_GRP1_PERIPH_GPIOA);
  LL_AHB2_GRP1_EnableClock(LL_AHB2_GRP1_PERIPH_GPIOB);
  /**USART1 GPIO Configuration
  PA9   ------> USART1_TX
  PB7   ------> USART1_RX
  */
  GPIO_InitStruct.Pin = LL_GPIO_PIN_9;
  GPIO_InitStruct.Mode = LL_GPIO_MODE_ALTERNATE;
  GPIO_InitStruct.Speed = LL_GPIO_SPEED_FREQ_VERY_HIGH;
  GPIO_InitStruct.OutputType = LL_GPIO_OUTPUT_PUSHPULL;
  GPIO_InitStruct.Pull = LL_GPIO_PULL_NO;
  GPIO_InitStruct.Alternate = LL_GPIO_AF_7;
  LL_GPIO_Init(GPIOA, &GPIO_InitStruct);

  GPIO_InitStruct.Pin = LL_GPIO_PIN_7;
  GPIO_InitStruct.Mode = LL_GPIO_MODE_ALTERNATE;
  GPIO_InitStruct.Speed = LL_GPIO_SPEED_FREQ_VERY_HIGH;
  GPIO_InitStruct.OutputType = LL_GPIO_OUTPUT_PUSHPULL;
  GPIO_InitStruct.Pull = LL_GPIO_PULL_NO;
  GPIO_InitStruct.Alternate = LL_GPIO_AF_7;
  LL_GPIO_Init(GPIOB, &GPIO_InitStruct);

  /* USART1 interrupt Init */
  NVIC_SetPriority(USART1_IRQn, NVIC_EncodePriority(NVIC_GetPriorityGrouping(),0, 0));
  NVIC_EnableIRQ(USART1_IRQn);

  USART_InitStruct.BaudRate = 115200;
  USART_InitStruct.DataWidth = LL_USART_DATAWIDTH_8B;
  USART_InitStruct.StopBits = LL_USART_STOPBITS_1;
  USART_InitStruct.Parity = LL_USART_PARITY_NONE;
  USART_InitStruct.TransferDirection = LL_USART_DIRECTION_TX_RX;
  USART_InitStruct.HardwareFlowControl = LL_USART_HWCONTROL_NONE;
  USART_InitStruct.OverSampling = LL_USART_OVERSAMPLING_16;
  LL_USART_Init(USART1, &USART_InitStruct);
  LL_USART_ConfigAsyncMode(USART1);
  LL_USART_Enable(USART1);

}

static void MX_USART2_UART_Init(void)
{

  LL_USART_InitTypeDef USART_InitStruct = {0};

  LL_GPIO_InitTypeDef GPIO_InitStruct = {0};

  LL_RCC_SetUSARTClockSource(LL_RCC_USART2_CLKSOURCE_PCLK1);

  /* Peripheral clock enable */
  LL_APB1_GRP1_EnableClock(LL_APB1_GRP1_PERIPH_USART2);

  LL_AHB2_GRP1_EnableClock(LL_AHB2_GRP1_PERIPH_GPIOD);
  /**USART2 GPIO Configuration
  PD5   ------> USART2_TX
  PD6   ------> USART2_RX
  */
  GPIO_InitStruct.Pin = LL_GPIO_PIN_5|LL_GPIO_PIN_6;
  GPIO_InitStruct.Mode = LL_GPIO_MODE_ALTERNATE;
  GPIO_InitStruct.Speed = LL_GPIO_SPEED_FREQ_VERY_HIGH;
  GPIO_InitStruct.OutputType = LL_GPIO_OUTPUT_PUSHPULL;
  GPIO_InitStruct.Pull = LL_GPIO_PULL_NO;
  GPIO_InitStruct.Alternate = LL_GPIO_AF_7;
  LL_GPIO_Init(GPIOD, &GPIO_InitStruct);

  /* USART2 interrupt Init */
  NVIC_SetPriority(USART2_IRQn, NVIC_EncodePriority(NVIC_GetPriorityGrouping(),0, 0));
  NVIC_EnableIRQ(USART2_IRQn);

  USART_InitStruct.BaudRate = 115200;
  USART_InitStruct.DataWidth = LL_USART_DATAWIDTH_8B;
  USART_InitStruct.StopBits = LL_USART_STOPBITS_1;
  USART_InitStruct.Parity = LL_USART_PARITY_NONE;
  USART_InitStruct.TransferDirection = LL_USART_DIRECTION_TX_RX;
  USART_InitStruct.HardwareFlowControl = LL_USART_HWCONTROL_NONE;
  USART_InitStruct.OverSampling = LL_USART_OVERSAMPLING_16;
  LL_USART_Init(USART2, &USART_InitStruct);
  LL_USART_ConfigAsyncMode(USART2);
  LL_USART_Enable(USART2);

}

static void MX_USART3_UART_Init(void)
{

  LL_USART_InitTypeDef USART_InitStruct = {0};

  LL_GPIO_InitTypeDef GPIO_InitStruct = {0};

  LL_RCC_SetUSARTClockSource(LL_RCC_USART3_CLKSOURCE_PCLK1);

  /* Peripheral clock enable */
  LL_APB1_GRP1_EnableClock(LL_APB1_GRP1_PERIPH_USART3);

  LL_AHB2_GRP1_EnableClock(LL_AHB2_GRP1_PERIPH_GPIOB);
  /**USART3 GPIO Configuration
  PB10   ------> USART3_TX
  PB11   ------> USART3_RX
  */
  GPIO_InitStruct.Pin = LL_GPIO_PIN_10|LL_GPIO_PIN_11;
  GPIO_InitStruct.Mode = LL_GPIO_MODE_ALTERNATE;
  GPIO_InitStruct.Speed = LL_GPIO_SPEED_FREQ_VERY_HIGH;
  GPIO_InitStruct.OutputType = LL_GPIO_OUTPUT_PUSHPULL;
  GPIO_InitStruct.Pull = LL_GPIO_PULL_NO;
  GPIO_InitStruct.Alternate = LL_GPIO_AF_7;
  LL_GPIO_Init(GPIOB, &GPIO_InitStruct);

  /* USART3 interrupt Init */
  NVIC_SetPriority(USART3_IRQn, NVIC_EncodePriority(NVIC_GetPriorityGrouping(),0, 0));
  NVIC_EnableIRQ(USART3_IRQn);

  USART_InitStruct.BaudRate = 115200;
  USART_InitStruct.DataWidth = LL_USART_DATAWIDTH_8B;
  USART_InitStruct.StopBits = LL_USART_STOPBITS_1;
  USART_InitStruct.Parity = LL_USART_PARITY_NONE;
  USART_InitStruct.TransferDirection = LL_USART_DIRECTION_TX_RX;
  USART_InitStruct.HardwareFlowControl = LL_USART_HWCONTROL_NONE;
  USART_InitStruct.OverSampling = LL_USART_OVERSAMPLING_16;
  LL_USART_Init(USART3, &USART_InitStruct);
  LL_USART_ConfigAsyncMode(USART3);
  LL_USART_Enable(USART3);

}

static void MX_USB_OTG_FS_USB_Init(void)
{

}

static void MX_DMA_Init(void)
{

  /* Init with LL driver */
  /* DMA controller clock enable */
  LL_AHB1_GRP1_EnableClock(LL_AHB1_GRP1_PERIPH_DMA1);

  /* DMA interrupt init */
  /* DMA1_Channel1_IRQn interrupt configuration */
  NVIC_SetPriority(DMA1_Channel1_IRQn, NVIC_EncodePriority(NVIC_GetPriorityGrouping(),0, 0));
  NVIC_EnableIRQ(DMA1_Channel1_IRQn);
  /* DMA1_Channel3_IRQn interrupt configuration */
  NVIC_SetPriority(DMA1_Channel3_IRQn, NVIC_EncodePriority(NVIC_GetPriorityGrouping(),0, 0));
  NVIC_EnableIRQ(DMA1_Channel3_IRQn);

}

static void MX_GPIO_Init(void)
{
  LL_GPIO_InitTypeDef GPIO_InitStruct = {0};

  /* GPIO Ports Clock Enable */
  LL_AHB2_GRP1_EnableClock(LL_AHB2_GRP1_PERIPH_GPIOE);
  LL_AHB2_GRP1_EnableClock(LL_AHB2_GRP1_PERIPH_GPIOC);
  LL_AHB2_GRP1_EnableClock(LL_AHB2_GRP1_PERIPH_GPIOH);
  LL_AHB2_GRP1_EnableClock(LL_AHB2_GRP1_PERIPH_GPIOA);
  LL_AHB2_GRP1_EnableClock(LL_AHB2_GRP1_PERIPH_GPIOB);
  LL_AHB2_GRP1_EnableClock(LL_AHB2_GRP1_PERIPH_GPIOD);

  /**/
  LL_GPIO_ResetOutputPin(GPIOE, DEBUG_LED2_Pin|DEBUG_LED3_Pin|DEBUG_LED4_Pin|DEBUG_LED5_Pin
                          |EN_5V_PM_Pin|EN_UNREG1_PM_Pin|EN_UNREG2_PM_Pin|EN_3V3_1_PM_Pin
                          |EN_3V3_2_BUCK_PM_Pin|DEBUG_LED1_Pin);

  /**/
  LL_GPIO_ResetOutputPin(EN_5V_BOOST_PM_GPIO_Port, EN_5V_BOOST_PM_Pin);

  /**/
  LL_GPIO_ResetOutputPin(GPIOD, EN_MCU_3V3_PM_Pin|EN_MCU_BUCK_PM_Pin|EN_3V3_2_PM_Pin|EN_3V3_1_BUCK_PM_Pin);

  /**/
  LL_GPIO_ResetOutputPin(GPIOC, DONE_Pin|WAKE_Pin);

  /**/
  GPIO_InitStruct.Pin = DEBUG_LED2_Pin|DEBUG_LED3_Pin|DEBUG_LED4_Pin|DEBUG_LED5_Pin
                          |EN_5V_PM_Pin|EN_UNREG1_PM_Pin|EN_UNREG2_PM_Pin|EN_3V3_1_PM_Pin
                          |EN_3V3_2_BUCK_PM_Pin|DEBUG_LED1_Pin;
  GPIO_InitStruct.Mode = LL_GPIO_MODE_OUTPUT;
  GPIO_InitStruct.Speed = LL_GPIO_SPEED_FREQ_LOW;
  GPIO_InitStruct.OutputType = LL_GPIO_OUTPUT_PUSHPULL;
  GPIO_InitStruct.Pull = LL_GPIO_PULL_NO;
  LL_GPIO_Init(GPIOE, &GPIO_InitStruct);

  /**/
  GPIO_InitStruct.Pin = EN_5V_BOOST_PM_Pin;
  GPIO_InitStruct.Mode = LL_GPIO_MODE_OUTPUT;
  GPIO_InitStruct.Speed = LL_GPIO_SPEED_FREQ_LOW;
  GPIO_InitStruct.OutputType = LL_GPIO_OUTPUT_PUSHPULL;
  GPIO_InitStruct.Pull = LL_GPIO_PULL_NO;
  LL_GPIO_Init(EN_5V_BOOST_PM_GPIO_Port, &GPIO_InitStruct);

  /**/
  GPIO_InitStruct.Pin = EN_MCU_3V3_PM_Pin|EN_MCU_BUCK_PM_Pin|EN_3V3_2_PM_Pin|EN_3V3_1_BUCK_PM_Pin;
  GPIO_InitStruct.Mode = LL_GPIO_MODE_OUTPUT;
  GPIO_InitStruct.Speed = LL_GPIO_SPEED_FREQ_LOW;
  GPIO_InitStruct.OutputType = LL_GPIO_OUTPUT_PUSHPULL;
  GPIO_InitStruct.Pull = LL_GPIO_PULL_NO;
  LL_GPIO_Init(GPIOD, &GPIO_InitStruct);

  /**/
  GPIO_InitStruct.Pin = DONE_Pin|WAKE_Pin;
  GPIO_InitStruct.Mode = LL_GPIO_MODE_OUTPUT;
  GPIO_InitStruct.Speed = LL_GPIO_SPEED_FREQ_LOW;
  GPIO_InitStruct.OutputType = LL_GPIO_OUTPUT_PUSHPULL;
  GPIO_InitStruct.Pull = LL_GPIO_PULL_NO;
  LL_GPIO_Init(GPIOC, &GPIO_InitStruct);

  /**/
  GPIO_InitStruct.Pin = LL_GPIO_PIN_10|LL_GPIO_PIN_11|LL_GPIO_PIN_12;
  GPIO_InitStruct.Mode = LL_GPIO_MODE_ALTERNATE;
  GPIO_InitStruct.Speed = LL_GPIO_SPEED_FREQ_VERY_HIGH;
  GPIO_InitStruct.OutputType = LL_GPIO_OUTPUT_PUSHPULL;
  GPIO_InitStruct.Pull = LL_GPIO_PULL_NO;
  GPIO_InitStruct.Alternate = LL_GPIO_AF_10;
  LL_GPIO_Init(GPIOA, &GPIO_InitStruct);

}

void Error_Handler(void)
{
  __disable_irq();
  while (1)
  {
  }
}
